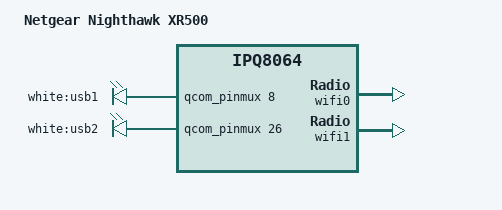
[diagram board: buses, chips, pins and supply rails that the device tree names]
// SPDX-License-Identifier: GPL-2.0-or-later OR MIT

#include "qcom-ipq8065-nighthawk.dtsi"

/ {
	model = "Netgear Nighthawk XR500";
	compatible = "netgear,xr500", "qcom,ipq8065", "qcom,ipq8064";

};

&leds {
	usb1 {
		label = "white:usb1";
		gpios = <&qcom_pinmux 8 GPIO_ACTIVE_HIGH>;
	};

	usb2 {
		label = "white:usb2";
		gpios = <&qcom_pinmux 26 GPIO_ACTIVE_HIGH>;
	};
};

&partitions {
	partition@1880000 {
		label = "ubi";
		reg = <0x1880000 0xce00000>;
	};

	partition@e680000 {
		label = "reserve";
		reg = <0xe680000 0x0780000>;
		read-only;
	};
};

&wifi0 {
	nvmem-cells = <&macaddr_art_c>, <&precal_art_1000>;
	nvmem-cell-names = "mac-address", "pre-calibration";
};

&wifi1 {
	nvmem-cells = <&macaddr_art_0>, <&precal_art_5000>;
	nvmem-cell-names = "mac-address", "pre-calibration";
};

&art {
	macaddr_art_c: macaddr@c {
		reg = <0xc 0x6>;
	};
};
